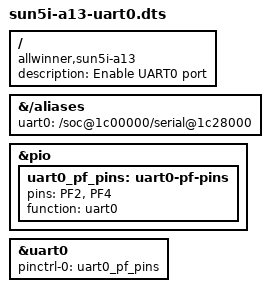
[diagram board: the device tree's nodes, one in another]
/dts-v1/;
/plugin/;

/ {
	compatible = "allwinner,sun5i-a13";
	description = "Enable UART0 port";

	fragment@0 {
		target-path = "/aliases";
		__overlay__ {
			uart0 = "/soc@1c00000/serial@1c28000";
		};
	};

	fragment@1 {
		target = <&pio>;
		__overlay__ {
			uart0_pf_pins: uart0-pf-pins {
				pins = "PF2", "PF4";
				function = "uart0";
			};
		};
	};

	fragment@2 {
		target = <&uart0>;
		 __overlay__ {
			pinctrl-names = "default";
			pinctrl-0 = <&uart0_pf_pins>;
			status = "okay";
		};
	};
};
